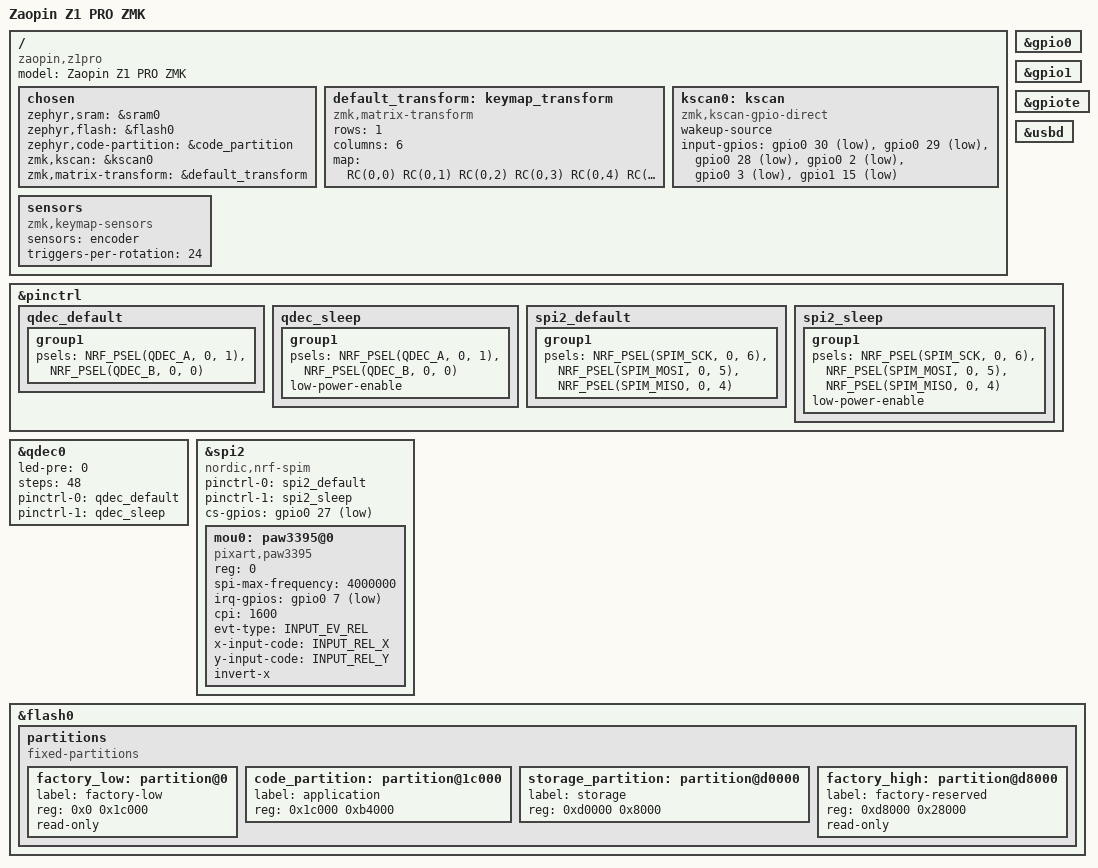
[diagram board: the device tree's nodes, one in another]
/dts-v1/;
#include <nordic/nrf52840_qiaa.dtsi>
#include <zephyr/dt-bindings/gpio/gpio.h>
#include <zephyr/dt-bindings/pinctrl/nrf-pinctrl.h>
#include <zephyr/dt-bindings/input/input-event-codes.h>
#include <dt-bindings/zmk/matrix_transform.h>

/ {
    model = "Zaopin Z1 PRO ZMK";
    compatible = "zaopin,z1pro";
    chosen {
        zephyr,sram = &sram0;
        zephyr,flash = &flash0;
        zephyr,code-partition = &code_partition;
        zmk,kscan = &kscan0;
        zmk,matrix-transform = &default_transform;
    };
    default_transform: keymap_transform {
        compatible = "zmk,matrix-transform";
        rows = <1>; columns = <6>;
        map = <RC(0,0) RC(0,1) RC(0,2) RC(0,3) RC(0,4) RC(0,5)>;
    };
    kscan0: kscan {
        compatible = "zmk,kscan-gpio-direct";
        wakeup-source;
        input-gpios = <&gpio0 30 (GPIO_ACTIVE_LOW | GPIO_PULL_UP)>,
                      <&gpio0 29 (GPIO_ACTIVE_LOW | GPIO_PULL_UP)>,
                      <&gpio0 28 (GPIO_ACTIVE_LOW | GPIO_PULL_UP)>,
                      <&gpio0 2 (GPIO_ACTIVE_LOW | GPIO_PULL_UP)>,
                      <&gpio0 3 (GPIO_ACTIVE_LOW | GPIO_PULL_UP)>,
                      <&gpio1 15 (GPIO_ACTIVE_LOW | GPIO_PULL_UP)>;
    };
    sensors {
        compatible = "zmk,keymap-sensors";
        sensors = <&encoder>;
        triggers-per-rotation = <24>;
    };
};

&gpio0 { status = "okay"; };
&gpio1 { status = "okay"; };
&gpiote { status = "okay"; };
zephyr_udc0: &usbd { status = "okay"; };
&pinctrl {
    qdec_default: qdec_default { group1 { psels = <NRF_PSEL(QDEC_A, 0, 1)>, <NRF_PSEL(QDEC_B, 0, 0)>; }; };
    qdec_sleep: qdec_sleep { group1 { psels = <NRF_PSEL(QDEC_A, 0, 1)>, <NRF_PSEL(QDEC_B, 0, 0)>; low-power-enable; }; };
    spi2_default: spi2_default { group1 { psels = <NRF_PSEL(SPIM_SCK, 0, 6)>, <NRF_PSEL(SPIM_MOSI, 0, 5)>, <NRF_PSEL(SPIM_MISO, 0, 4)>; }; };
    spi2_sleep: spi2_sleep { group1 { psels = <NRF_PSEL(SPIM_SCK, 0, 6)>, <NRF_PSEL(SPIM_MOSI, 0, 5)>, <NRF_PSEL(SPIM_MISO, 0, 4)>; low-power-enable; }; };
};
encoder: &qdec0 {
    status = "okay";
    led-pre = <0>; steps = <48>;
    pinctrl-0 = <&qdec_default>; pinctrl-1 = <&qdec_sleep>;
    pinctrl-names = "default", "sleep";
};
&spi2 {
    compatible = "nordic,nrf-spim";
    status = "okay";
    pinctrl-0 = <&spi2_default>; pinctrl-1 = <&spi2_sleep>;
    pinctrl-names = "default", "sleep";
    cs-gpios = <&gpio0 27 GPIO_ACTIVE_LOW>;
    mou0: paw3395@0 {
        compatible = "pixart,paw3395";
        status = "okay";
        reg = <0>; spi-max-frequency = <4000000>;
        irq-gpios = <&gpio0 7 (GPIO_ACTIVE_LOW | GPIO_PULL_UP)>;
        cpi = <1600>;
        evt-type = <INPUT_EV_REL>;
        x-input-code = <INPUT_REL_X>; y-input-code = <INPUT_REL_Y>;
        invert-x;
    };
};
&flash0 {
    partitions {
        compatible = "fixed-partitions";
        #address-cells = <1>; #size-cells = <1>;
        factory_low: partition@0 { label = "factory-low"; reg = <0x0 0x1c000>; read-only; };
        code_partition: partition@1c000 { label = "application"; reg = <0x1c000 0xb4000>; };
        storage_partition: partition@d0000 { label = "storage"; reg = <0xd0000 0x8000>; };
        factory_high: partition@d8000 { label = "factory-reserved"; reg = <0xd8000 0x28000>; read-only; };
    };
};
